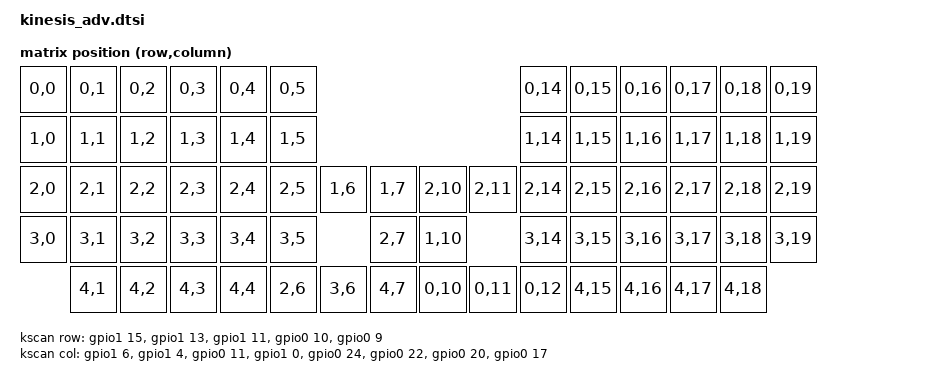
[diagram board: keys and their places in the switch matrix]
// This file was generated from a template. Edit it to match your keyboard.
// See https://zmk.dev/docs/development/hardware-integration/new-shield for more
// instructions.

#include <dt-bindings/zmk/matrix_transform.h>

#include "kinesis_adv-layouts.dtsi"

/ {
    chosen {
        zmk,physical-layout = &default_layout;
    };

    kscan: kscan {
        // If the hardware does not use a switch matrix, change this to the
        // appropriate driver and update the properties below to match.
        // See https://zmk.dev/docs/config/kscan for supported key scan drivers.
        compatible = "zmk,kscan-gpio-matrix";
        // Set this to "col2row" or "row2col" to match the hardware. If using
        // "row2col", change the col-gpios in the _left.overlay and _right.overlay
        // files to (GPIO_ACTIVE_HIGH | GPIO_PULL_DOWN) and the row-gpios here to
        // GPIO_ACTIVE_HIGH.
        diode-direction = "col2row";
        wakeup-source;

        // Replace these comments with the GPIO pins in the matrix.
        // See https://zmk.dev/docs/development/hardware-integration/new-shield#shield-overlays

	row-gpios
            = <&gpio1 15 (GPIO_ACTIVE_HIGH | GPIO_PULL_DOWN)>
            , <&gpio1 13 (GPIO_ACTIVE_HIGH | GPIO_PULL_DOWN)>
            , <&gpio1 11 (GPIO_ACTIVE_HIGH | GPIO_PULL_DOWN)>
            , <&gpio0 10 (GPIO_ACTIVE_HIGH | GPIO_PULL_DOWN)>
            , <&gpio0 9 (GPIO_ACTIVE_HIGH | GPIO_PULL_DOWN)>
            ;

        col-gpios
            = <&gpio1 6 (GPIO_ACTIVE_HIGH)>
            , <&gpio1 4 (GPIO_ACTIVE_HIGH)>
            , <&gpio0 11 (GPIO_ACTIVE_HIGH)>
            , <&gpio1 0 (GPIO_ACTIVE_HIGH)>
            , <&gpio0 24 (GPIO_ACTIVE_HIGH)>
            , <&gpio0 22 (GPIO_ACTIVE_HIGH)>
            , <&gpio0 20 (GPIO_ACTIVE_HIGH)>
            , <&gpio0 17 (GPIO_ACTIVE_HIGH)>
            ;
    };

    default_transform: default_transform {
        // See https://zmk.dev/docs/development/hardware-integration/new-shield#matrix-transform
        // for how to configure this
        compatible = "zmk,matrix-transform";
        columns = <16>;
        rows = <5>;

	map = <
            RC(0,0) RC(0,1) RC(0,2) RC(0,3) RC(0,4) RC(0,5)                                                    RC(0,14) RC(0,15) RC(0,16) RC(0,17) RC(0,18) RC(0,19)
            RC(1,0) RC(1,1) RC(1,2) RC(1,3) RC(1,4) RC(1,5)                                                    RC(1,14) RC(1,15) RC(1,16) RC(1,17) RC(1,18) RC(1,19)
            RC(2,0) RC(2,1) RC(2,2) RC(2,3) RC(2,4) RC(2,5)         RC(1,6) RC(1,7) RC(2,10) RC(2,11)          RC(2,14) RC(2,15) RC(2,16) RC(2,17) RC(2,18) RC(2,19)
            RC(3,0) RC(3,1) RC(3,2) RC(3,3) RC(3,4) RC(3,5)                 RC(2,7) RC(1,10)                   RC(3,14) RC(3,15) RC(3,16) RC(3,17) RC(3,18) RC(3,19)
                    RC(4,1) RC(4,2) RC(4,3) RC(4,4)         RC(2,6) RC(3,6) RC(4,7) RC(0,10) RC(0,11) RC(0,12)          RC(4,15) RC(4,16) RC(4,17) RC(4,18)
        >;
    };
};
